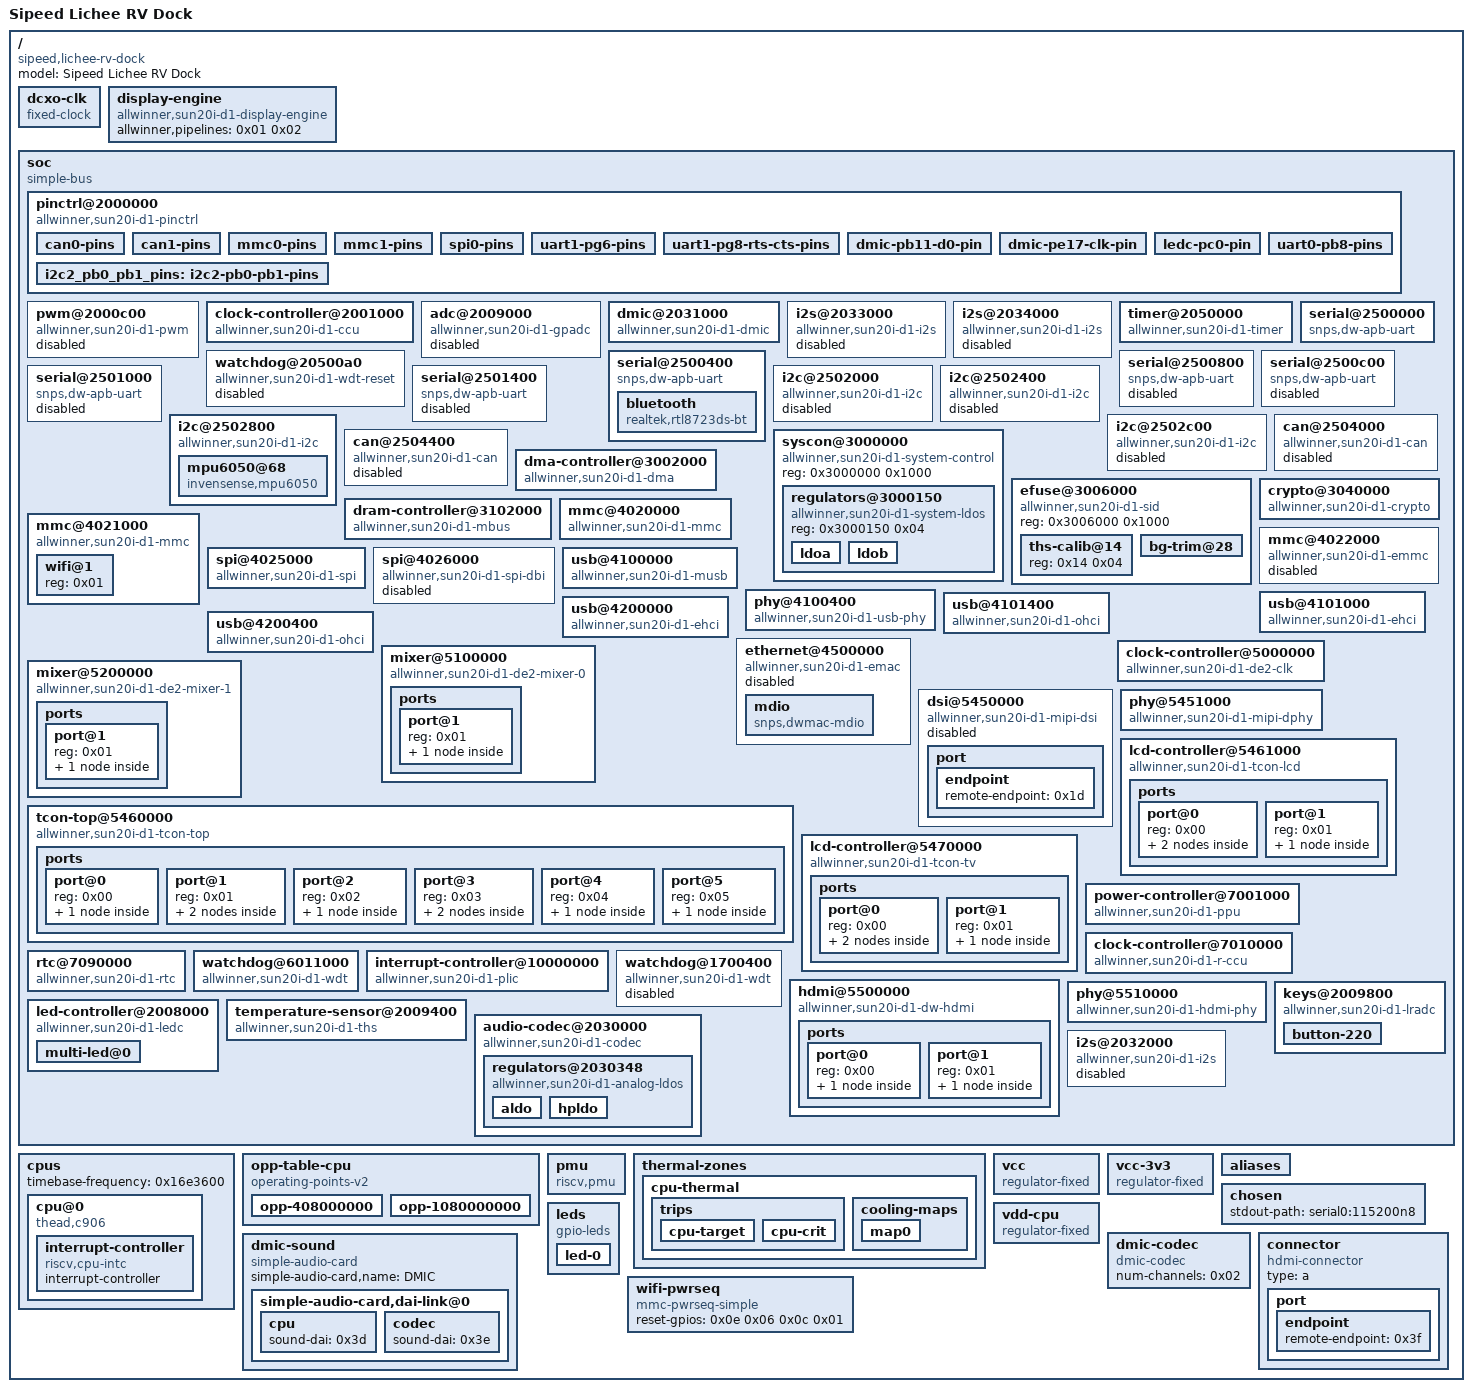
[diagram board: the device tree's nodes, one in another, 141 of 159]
/dts-v1/;

/ {
	#address-cells = <0x01>;
	#size-cells = <0x01>;
	model = "Sipeed Lichee RV Dock";
	compatible = "sipeed,lichee-rv-dock\0sipeed,lichee-rv\0allwinner,sun20i-d1";

	dcxo-clk {
		compatible = "fixed-clock";
		clock-output-names = "dcxo";
		#clock-cells = <0x00>;
		clock-frequency = <0x16e3600>;
		phandle = <0x05>;
	};

	display-engine {
		compatible = "allwinner,sun20i-d1-display-engine";
		allwinner,pipelines = <0x01 0x02>;
		status = "okay";
	};

	soc {
		compatible = "simple-bus";
		ranges;
		dma-noncoherent;
		#address-cells = <0x01>;
		#size-cells = <0x01>;
		interrupt-parent = <0x03>;

		pinctrl@2000000 {
			compatible = "allwinner,sun20i-d1-pinctrl";
			reg = <0x2000000 0x800>;
			interrupts = <0x55 0x04 0x57 0x04 0x59 0x04 0x5b 0x04 0x5d 0x04 0x5f 0x04>;
			clocks = <0x04 0x18 0x05 0x06 0x00>;
			clock-names = "apb\0hosc\0losc";
			gpio-controller;
			interrupt-controller;
			#gpio-cells = <0x03>;
			#interrupt-cells = <0x03>;
			vcc-pb-supply = <0x07>;
			vcc-pc-supply = <0x07>;
			vcc-pd-supply = <0x07>;
			vcc-pe-supply = <0x07>;
			vcc-pf-supply = <0x07>;
			vcc-pg-supply = <0x07>;
			phandle = <0x0e>;

			can0-pins {
				pins = "PB2\0PB3";
				function = "can0";
				phandle = <0x0f>;
			};

			can1-pins {
				pins = "PB4\0PB5";
				function = "can1";
				phandle = <0x10>;
			};

			mmc0-pins {
				pins = "PF0\0PF1\0PF2\0PF3\0PF4\0PF5";
				function = "mmc0";
				phandle = <0x11>;
			};

			mmc1-pins {
				pins = "PG0\0PG1\0PG2\0PG3\0PG4\0PG5";
				function = "mmc1";
				phandle = <0x13>;
			};

			spi0-pins {
				pins = "PC2\0PC3\0PC4\0PC5\0PC6\0PC7";
				function = "spi0";
				phandle = <0x14>;
			};

			uart1-pg6-pins {
				pins = "PG6\0PG7";
				function = "uart1";
				phandle = <0x0c>;
			};

			uart1-pg8-rts-cts-pins {
				pins = "PG8\0PG9";
				function = "uart1";
				phandle = <0x0d>;
			};

			dmic-pb11-d0-pin {
				pins = "PB11";
				function = "dmic";
				phandle = <0x09>;
			};

			dmic-pe17-clk-pin {
				pins = "PE17";
				function = "dmic";
				phandle = <0x0a>;
			};

			ledc-pc0-pin {
				pins = "PC0";
				function = "ledc";
				phandle = <0x32>;
			};

			uart0-pb8-pins {
				pins = "PB8\0PB9";
				function = "uart0";
				phandle = <0x0b>;
			};

			i2c2_pb0_pb1_pins: i2c2-pb0-pb1-pins {
    				pins = "PB0", "PB1";
    				function = "i2c2";
			};
		};

		pwm@2000c00 {
			compatible = "allwinner,sun20i-d1-pwm";
			reg = <0x2000c00 0x400>;
			clocks = <0x04 0x2d 0x05 0x04 0x18>;
			clock-names = "bus\0hosc\0apb0";
			resets = <0x04 0x0d>;
			status = "disabled";
			#pwm-cells = <0x03>;
		};

		clock-controller@2001000 {
			compatible = "allwinner,sun20i-d1-ccu";
			reg = <0x2001000 0x1000>;
			clocks = <0x05 0x06 0x00 0x06 0x02>;
			clock-names = "hosc\0losc\0iosc";
			#clock-cells = <0x01>;
			#reset-cells = <0x01>;
			phandle = <0x04>;
		};

		adc@2009000 {
			compatible = "allwinner,sun20i-d1-gpadc";
			reg = <0x2009000 0x400>;
			clocks = <0x04 0x50>;
			resets = <0x04 0x20>;
			interrupts = <0x49 0x04>;
			status = "disabled";
			#io-channel-cells = <0x01>;
		};

		dmic@2031000 {
			compatible = "allwinner,sun20i-d1-dmic\0allwinner,sun50i-h6-dmic";
			reg = <0x2031000 0x400>;
			interrupts = <0x28 0x04>;
			clocks = <0x04 0x5d 0x04 0x5c>;
			clock-names = "bus\0mod";
			resets = <0x04 0x26>;
			dmas = <0x08 0x08>;
			dma-names = "rx";
			status = "okay";
			#sound-dai-cells = <0x00>;
			pinctrl-0 = <0x09 0x0a>;
			pinctrl-names = "default";
			phandle = <0x3d>;
		};

		i2s@2033000 {
			compatible = "allwinner,sun20i-d1-i2s\0allwinner,sun50i-r329-i2s";
			reg = <0x2033000 0x1000>;
			interrupts = <0x2b 0x04>;
			clocks = <0x04 0x57 0x04 0x53>;
			clock-names = "apb\0mod";
			resets = <0x04 0x23>;
			dmas = <0x08 0x04 0x08 0x04>;
			dma-names = "rx\0tx";
			status = "disabled";
			#sound-dai-cells = <0x00>;
		};

		i2s@2034000 {
			compatible = "allwinner,sun20i-d1-i2s\0allwinner,sun50i-r329-i2s";
			reg = <0x2034000 0x1000>;
			interrupts = <0x2c 0x04>;
			clocks = <0x04 0x58 0x04 0x54>;
			clock-names = "apb\0mod";
			resets = <0x04 0x24>;
			dmas = <0x08 0x05 0x08 0x05>;
			dma-names = "rx\0tx";
			status = "disabled";
			#sound-dai-cells = <0x00>;
		};

		timer@2050000 {
			compatible = "allwinner,sun20i-d1-timer\0allwinner,sun8i-a23-timer";
			reg = <0x2050000 0xa0>;
			interrupts = <0x4b 0x04 0x4c 0x04>;
			clocks = <0x05>;
		};

		watchdog@20500a0 {
			compatible = "allwinner,sun20i-d1-wdt-reset\0allwinner,sun20i-d1-wdt";
			reg = <0x20500a0 0x20>;
			interrupts = <0x4f 0x04>;
			clocks = <0x05 0x06 0x00>;
			clock-names = "hosc\0losc";
			status = "reserved";
		};

		serial@2500000 {
			compatible = "snps,dw-apb-uart";
			reg = <0x2500000 0x400>;
			reg-io-width = <0x04>;
			reg-shift = <0x02>;
			interrupts = <0x12 0x04>;
			clocks = <0x04 0x3e>;
			resets = <0x04 0x12>;
			dmas = <0x08 0x0e 0x08 0x0e>;
			dma-names = "tx\0rx";
			status = "okay";
			pinctrl-0 = <0x0b>;
			pinctrl-names = "default";
		};

		serial@2500400 {
			compatible = "snps,dw-apb-uart";
			reg = <0x2500400 0x400>;
			reg-io-width = <0x04>;
			reg-shift = <0x02>;
			interrupts = <0x13 0x04>;
			clocks = <0x04 0x3f>;
			resets = <0x04 0x13>;
			dmas = <0x08 0x0f 0x08 0x0f>;
			dma-names = "tx\0rx";
			status = "okay";
			uart-has-rtscts;
			pinctrl-0 = <0x0c 0x0d>;
			pinctrl-names = "default";

			bluetooth {
				compatible = "realtek,rtl8723ds-bt";
				device-wake-gpios = <0x0e 0x06 0x0f 0x00>;
				enable-gpios = <0x0e 0x06 0x12 0x00>;
				host-wake-gpios = <0x0e 0x06 0x11 0x00>;
			};
		};

		serial@2500800 {
			compatible = "snps,dw-apb-uart";
			reg = <0x2500800 0x400>;
			reg-io-width = <0x04>;
			reg-shift = <0x02>;
			interrupts = <0x14 0x04>;
			clocks = <0x04 0x40>;
			resets = <0x04 0x14>;
			dmas = <0x08 0x10 0x08 0x10>;
			dma-names = "tx\0rx";
			status = "disabled";
		};

		serial@2500c00 {
			compatible = "snps,dw-apb-uart";
			reg = <0x2500c00 0x400>;
			reg-io-width = <0x04>;
			reg-shift = <0x02>;
			interrupts = <0x15 0x04>;
			clocks = <0x04 0x41>;
			resets = <0x04 0x15>;
			dmas = <0x08 0x11 0x08 0x11>;
			dma-names = "tx\0rx";
			status = "disabled";
		};

		serial@2501000 {
			compatible = "snps,dw-apb-uart";
			reg = <0x2501000 0x400>;
			reg-io-width = <0x04>;
			reg-shift = <0x02>;
			interrupts = <0x16 0x04>;
			clocks = <0x04 0x42>;
			resets = <0x04 0x16>;
			dmas = <0x08 0x12 0x08 0x12>;
			dma-names = "tx\0rx";
			status = "disabled";
		};

		serial@2501400 {
			compatible = "snps,dw-apb-uart";
			reg = <0x2501400 0x400>;
			reg-io-width = <0x04>;
			reg-shift = <0x02>;
			interrupts = <0x17 0x04>;
			clocks = <0x04 0x43>;
			resets = <0x04 0x17>;
			dmas = <0x08 0x13 0x08 0x13>;
			dma-names = "tx\0rx";
			status = "disabled";
		};

		i2c@2502000 {
			compatible = "allwinner,sun20i-d1-i2c\0allwinner,sun8i-v536-i2c\0allwinner,sun6i-a31-i2c";
			reg = <0x2502000 0x400>;
			interrupts = <0x19 0x04>;
			clocks = <0x04 0x44>;
			resets = <0x04 0x18>;
			dmas = <0x08 0x2b 0x08 0x2b>;
			dma-names = "rx\0tx";
			status = "disabled";
			#address-cells = <0x01>;
			#size-cells = <0x00>;
		};

		i2c@2502400 {
			compatible = "allwinner,sun20i-d1-i2c\0allwinner,sun8i-v536-i2c\0allwinner,sun6i-a31-i2c";
			reg = <0x2502400 0x400>;
			interrupts = <0x1a 0x04>;
			clocks = <0x04 0x45>;
			resets = <0x04 0x19>;
			dmas = <0x08 0x2c 0x08 0x2c>;
			dma-names = "rx\0tx";
			status = "disabled";
			#address-cells = <0x01>;
			#size-cells = <0x00>;
		};

		i2c@2502800 {
			compatible = "allwinner,sun20i-d1-i2c\0allwinner,sun8i-v536-i2c\0allwinner,sun6i-a31-i2c";
			reg = <0x2502800 0x400>;
			interrupts = <0x1b 0x04>;
			clocks = <0x04 0x46>;
			resets = <0x04 0x1a>;
			dmas = <0x08 0x2d 0x08 0x2d>;
			dma-names = "rx\0tx";
			pinctrl-names = "default";
    			pinctrl-0 = <&i2c2_pb0_pb1_pins>;
			status = "okay";
			#address-cells = <0x01>;
			#size-cells = <0x00>;
			
			mpu6050@68 {
        			compatible = "invensense,mpu6050";
        			reg = <0x68>;
        			mount-matrix = "1", "0", "0", "0", "1", "0", "0", "0", "1";
    			};	
		};

		i2c@2502c00 {
			compatible = "allwinner,sun20i-d1-i2c\0allwinner,sun8i-v536-i2c\0allwinner,sun6i-a31-i2c";
			reg = <0x2502c00 0x400>;
			interrupts = <0x1c 0x04>;
			clocks = <0x04 0x47>;
			resets = <0x04 0x1b>;
			dmas = <0x08 0x2e 0x08 0x2e>;
			dma-names = "rx\0tx";
			status = "disabled";
			#address-cells = <0x01>;
			#size-cells = <0x00>;
		};

		can@2504000 {
			compatible = "allwinner,sun20i-d1-can";
			reg = <0x2504000 0x400>;
			interrupts = <0x25 0x04>;
			clocks = <0x04 0x91>;
			resets = <0x04 0x42>;
			pinctrl-names = "default";
			pinctrl-0 = <0x0f>;
			status = "disabled";
		};

		can@2504400 {
			compatible = "allwinner,sun20i-d1-can";
			reg = <0x2504400 0x400>;
			interrupts = <0x26 0x04>;
			clocks = <0x04 0x92>;
			resets = <0x04 0x43>;
			pinctrl-names = "default";
			pinctrl-0 = <0x10>;
			status = "disabled";
		};

		syscon@3000000 {
			compatible = "allwinner,sun20i-d1-system-control";
			reg = <0x3000000 0x1000>;
			ranges;
			#address-cells = <0x01>;
			#size-cells = <0x01>;
			phandle = <0x17>;

			regulators@3000150 {
				compatible = "allwinner,sun20i-d1-system-ldos";
				reg = <0x3000150 0x04>;

				ldoa {
					regulator-always-on;
					regulator-min-microvolt = <0x1b7740>;
					regulator-max-microvolt = <0x1b7740>;
					ldo-in-supply = <0x07>;
					phandle = <0x2f>;
				};

				ldob {
				};
			};
		};

		dma-controller@3002000 {
			compatible = "allwinner,sun20i-d1-dma";
			reg = <0x3002000 0x1000>;
			interrupts = <0x42 0x04>;
			clocks = <0x04 0x25 0x04 0x30>;
			clock-names = "bus\0mbus";
			resets = <0x04 0x06>;
			dma-channels = <0x10>;
			dma-requests = <0x30>;
			#dma-cells = <0x01>;
			phandle = <0x08>;
		};

		efuse@3006000 {
			compatible = "allwinner,sun20i-d1-sid";
			reg = <0x3006000 0x1000>;
			#address-cells = <0x01>;
			#size-cells = <0x01>;

			ths-calib@14 {
				reg = <0x14 0x04>;
				phandle = <0x33>;
			};

			bg-trim@28 {
				reg = <0x28 0x04>;
				bits = <0x10 0x08>;
				phandle = <0x36>;
			};
		};

		crypto@3040000 {
			compatible = "allwinner,sun20i-d1-crypto";
			reg = <0x3040000 0x800>;
			interrupts = <0x44 0x04>;
			clocks = <0x04 0x22 0x04 0x21 0x04 0x32 0x06 0x02>;
			clock-names = "bus\0mod\0ram\0trng";
			resets = <0x04 0x04>;
		};

		dram-controller@3102000 {
			compatible = "allwinner,sun20i-d1-mbus";
			reg = <0x3102000 0x1000 0x3103000 0x1000>;
			reg-names = "mbus\0dram";
			interrupts = <0x3b 0x04>;
			clocks = <0x04 0x1a 0x04 0x2f 0x04 0x37>;
			clock-names = "mbus\0dram\0bus";
			dma-ranges = <0x00 0x40000000 0x80000000>;
			#address-cells = <0x01>;
			#size-cells = <0x01>;
			#interconnect-cells = <0x01>;
		};

		mmc@4020000 {
			compatible = "allwinner,sun20i-d1-mmc";
			reg = <0x4020000 0x1000>;
			interrupts = <0x38 0x04>;
			clocks = <0x04 0x3b 0x04 0x38>;
			clock-names = "ahb\0mmc";
			resets = <0x04 0x0f>;
			reset-names = "ahb";
			cap-sd-highspeed;
			max-frequency = <0x8f0d180>;
			no-mmc;
			status = "okay";
			#address-cells = <0x01>;
			#size-cells = <0x00>;
			broken-cd;
			bus-width = <0x04>;
			disable-wp;
			vmmc-supply = <0x07>;
			vqmmc-supply = <0x07>;
			pinctrl-0 = <0x11>;
			pinctrl-names = "default";
		};

		mmc@4021000 {
			compatible = "allwinner,sun20i-d1-mmc";
			reg = <0x4021000 0x1000>;
			interrupts = <0x39 0x04>;
			clocks = <0x04 0x3c 0x04 0x39>;
			clock-names = "ahb\0mmc";
			resets = <0x04 0x10>;
			reset-names = "ahb";
			cap-sd-highspeed;
			max-frequency = <0x8f0d180>;
			no-mmc;
			status = "okay";
			#address-cells = <0x01>;
			#size-cells = <0x00>;
			bus-width = <0x04>;
			mmc-pwrseq = <0x12>;
			non-removable;
			vmmc-supply = <0x07>;
			vqmmc-supply = <0x07>;
			pinctrl-0 = <0x13>;
			pinctrl-names = "default";

			wifi@1 {
				reg = <0x01>;
			};
		};

		mmc@4022000 {
			compatible = "allwinner,sun20i-d1-emmc\0allwinner,sun50i-a100-emmc";
			reg = <0x4022000 0x1000>;
			interrupts = <0x3a 0x04>;
			clocks = <0x04 0x3d 0x04 0x3a>;
			clock-names = "ahb\0mmc";
			resets = <0x04 0x11>;
			reset-names = "ahb";
			cap-mmc-highspeed;
			max-frequency = <0x8f0d180>;
			mmc-ddr-1_8v;
			mmc-ddr-3_3v;
			no-sd;
			no-sdio;
			status = "disabled";
			#address-cells = <0x01>;
			#size-cells = <0x00>;
		};

		spi@4025000 {
			compatible = "allwinner,sun20i-d1-spi\0allwinner,sun50i-r329-spi";
			reg = <0x4025000 0x1000>;
			interrupts = <0x1f 0x04>;
			clocks = <0x04 0x4a 0x04 0x48>;
			clock-names = "ahb\0mod";
			dmas = <0x08 0x16 0x08 0x16>;
			dma-names = "rx\0tx";
			resets = <0x04 0x1c>;
			status = "okay";
			#address-cells = <0x01>;
			#size-cells = <0x00>;
			pinctrl-0 = <0x14>;
			pinctrl-names = "default";
		};

		spi@4026000 {
			compatible = "allwinner,sun20i-d1-spi-dbi\0allwinner,sun50i-r329-spi-dbi\0allwinner,sun50i-r329-spi";
			reg = <0x4026000 0x1000>;
			interrupts = <0x20 0x04>;
			clocks = <0x04 0x4b 0x04 0x49>;
			clock-names = "ahb\0mod";
			dmas = <0x08 0x17 0x08 0x17>;
			dma-names = "rx\0tx";
			resets = <0x04 0x1d>;
			status = "disabled";
			#address-cells = <0x01>;
			#size-cells = <0x00>;
		};

		usb@4100000 {
			compatible = "allwinner,sun20i-d1-musb\0allwinner,sun8i-a33-musb";
			reg = <0x4100000 0x400>;
			interrupts = <0x2d 0x04>;
			interrupt-names = "mc";
			clocks = <0x04 0x67>;
			resets = <0x04 0x2e>;
			extcon = <0x15 0x00>;
			phys = <0x15 0x00>;
			phy-names = "usb";
			status = "okay";
			dr_mode = "otg";
		};

		phy@4100400 {
			compatible = "allwinner,sun20i-d1-usb-phy";
			reg = <0x4100400 0x100 0x4101800 0x100 0x4200800 0x100>;
			reg-names = "phy_ctrl\0pmu0\0pmu1";
			clocks = <0x05 0x05>;
			clock-names = "usb0_phy\0usb1_phy";
			resets = <0x04 0x28 0x04 0x29>;
			reset-names = "usb0_reset\0usb1_reset";
			status = "okay";
			#phy-cells = <0x01>;
			usb0_id_det-gpios = <0x0e 0x03 0x15 0x00>;
			usb0_vbus_det-gpios = <0x0e 0x03 0x14 0x00>;
			usb0_vbus-supply = <0x16>;
			usb1_vbus-supply = <0x16>;
			phandle = <0x15>;
		};

		usb@4101000 {
			compatible = "allwinner,sun20i-d1-ehci\0generic-ehci";
			reg = <0x4101000 0x100>;
			interrupts = <0x2e 0x04>;
			clocks = <0x04 0x63 0x04 0x65 0x04 0x61>;
			resets = <0x04 0x2a 0x04 0x2c>;
			phys = <0x15 0x00>;
			phy-names = "usb";
			status = "okay";
		};

		usb@4101400 {
			compatible = "allwinner,sun20i-d1-ohci\0generic-ohci";
			reg = <0x4101400 0x100>;
			interrupts = <0x2f 0x04>;
			clocks = <0x04 0x63 0x04 0x61>;
			resets = <0x04 0x2a>;
			phys = <0x15 0x00>;
			phy-names = "usb";
			status = "okay";
		};

		usb@4200000 {
			compatible = "allwinner,sun20i-d1-ehci\0generic-ehci";
			reg = <0x4200000 0x100>;
			interrupts = <0x31 0x04>;
			clocks = <0x04 0x64 0x04 0x66 0x04 0x62>;
			resets = <0x04 0x2b 0x04 0x2d>;
			phys = <0x15 0x01>;
			phy-names = "usb";
			status = "okay";
		};

		usb@4200400 {
			compatible = "allwinner,sun20i-d1-ohci\0generic-ohci";
			reg = <0x4200400 0x100>;
			interrupts = <0x32 0x04>;
			clocks = <0x04 0x64 0x04 0x62>;
			resets = <0x04 0x2b>;
			phys = <0x15 0x01>;
			phy-names = "usb";
			status = "okay";
		};

		ethernet@4500000 {
			compatible = "allwinner,sun20i-d1-emac\0allwinner,sun50i-a64-emac";
			reg = <0x4500000 0x10000>;
			interrupts = <0x3e 0x04>;
			interrupt-names = "macirq";
			clocks = <0x04 0x4d>;
			clock-names = "stmmaceth";
			resets = <0x04 0x1e>;
			reset-names = "stmmaceth";
			syscon = <0x17>;
			status = "disabled";

			mdio {
				compatible = "snps,dwmac-mdio";
				#address-cells = <0x01>;
				#size-cells = <0x00>;
			};
		};

		clock-controller@5000000 {
			compatible = "allwinner,sun20i-d1-de2-clk\0allwinner,sun50i-h5-de2-clk";
			reg = <0x5000000 0x10000>;
			clocks = <0x04 0x1c 0x04 0x1b>;
			clock-names = "bus\0mod";
			resets = <0x04 0x01>;
			#clock-cells = <0x01>;
			#reset-cells = <0x01>;
			phandle = <0x18>;
		};

		mixer@5100000 {
			compatible = "allwinner,sun20i-d1-de2-mixer-0";
			reg = <0x5100000 0x100000>;
			clocks = <0x18 0x00 0x18 0x06>;
			clock-names = "bus\0mod";
			resets = <0x18 0x00>;
			phandle = <0x01>;

			ports {
				#address-cells = <0x01>;
				#size-cells = <0x00>;

				port@1 {
					reg = <0x01>;

					endpoint {
						remote-endpoint = <0x19>;
						phandle = <0x1e>;
					};
				};
			};
		};

		mixer@5200000 {
			compatible = "allwinner,sun20i-d1-de2-mixer-1";
			reg = <0x5200000 0x100000>;
			clocks = <0x18 0x01 0x18 0x07>;
			clock-names = "bus\0mod";
			resets = <0x18 0x01>;
			phandle = <0x02>;

			ports {
				#address-cells = <0x01>;
				#size-cells = <0x00>;

				port@1 {
					reg = <0x01>;

					endpoint {
						remote-endpoint = <0x1a>;
						phandle = <0x21>;
					};
				};
			};
		};

		dsi@5450000 {
			compatible = "allwinner,sun20i-d1-mipi-dsi\0allwinner,sun50i-a100-mipi-dsi";
			reg = <0x5450000 0x1000>;
			interrupts = <0x6c 0x04>;
			clocks = <0x04 0x6f 0x1b 0x02>;
			clock-names = "bus\0mod";
			resets = <0x04 0x33>;
			phys = <0x1c>;
			phy-names = "dphy";
			status = "disabled";

			port {

				endpoint {
					remote-endpoint = <0x1d>;
					phandle = <0x28>;
				};
			};
		};

		phy@5451000 {
			compatible = "allwinner,sun20i-d1-mipi-dphy\0allwinner,sun50i-a100-mipi-dphy";
			reg = <0x5451000 0x1000>;
			interrupts = <0x6c 0x04>;
			clocks = <0x04 0x6f 0x04 0x6e>;
			clock-names = "bus\0mod";
			resets = <0x04 0x33>;
			#phy-cells = <0x00>;
			phandle = <0x1c>;
		};

		tcon-top@5460000 {
			compatible = "allwinner,sun20i-d1-tcon-top";
			reg = <0x5460000 0x1000>;
			clocks = <0x04 0x69 0x04 0x72 0x04 0x74 0x04 0x70>;
			clock-names = "bus\0tcon-tv0\0tve0\0dsi";
			clock-output-names = "tcon-top-tv0\0tcon-top-dsi";
			resets = <0x04 0x30>;
			#clock-cells = <0x01>;
			phandle = <0x1b>;

			ports {
				#address-cells = <0x01>;
				#size-cells = <0x00>;

				port@0 {
					reg = <0x00>;

					endpoint {
						remote-endpoint = <0x1e>;
						phandle = <0x19>;
					};
				};

				port@1 {
					reg = <0x01>;
					#address-cells = <0x01>;
					#size-cells = <0x00>;

					endpoint@0 {
						reg = <0x00>;
						remote-endpoint = <0x1f>;
						phandle = <0x26>;
					};

					endpoint@2 {
						reg = <0x02>;
						remote-endpoint = <0x20>;
						phandle = <0x29>;
					};
				};

				port@2 {
					reg = <0x02>;
					#address-cells = <0x01>;
					#size-cells = <0x00>;

					endpoint@1 {
						reg = <0x01>;
						remote-endpoint = <0x21>;
						phandle = <0x1a>;
					};
				};

				port@3 {
					reg = <0x03>;
					#address-cells = <0x01>;
					#size-cells = <0x00>;

					endpoint@0 {
						reg = <0x00>;
						remote-endpoint = <0x22>;
						phandle = <0x27>;
					};

					endpoint@2 {
						reg = <0x02>;
						remote-endpoint = <0x23>;
						phandle = <0x2a>;
					};
				};

				port@4 {
					reg = <0x04>;

					endpoint {
						remote-endpoint = <0x24>;
						phandle = <0x2b>;
					};
				};

				port@5 {
					reg = <0x05>;

					endpoint {
						remote-endpoint = <0x25>;
						phandle = <0x30>;
					};
				};
			};
		};

		lcd-controller@5461000 {
			compatible = "allwinner,sun20i-d1-tcon-lcd";
			reg = <0x5461000 0x1000>;
			interrupts = <0x6a 0x04>;
			clocks = <0x04 0x71 0x04 0x70>;
			clock-names = "ahb\0tcon-ch0";
			clock-output-names = "tcon-pixel-clock";
			resets = <0x04 0x34 0x04 0x36>;
			reset-names = "lcd\0lvds";
			phys = <0x1c>;
			phy-names = "lvds0";
			#clock-cells = <0x00>;

			ports {
				#address-cells = <0x01>;
				#size-cells = <0x00>;

				port@0 {
					reg = <0x00>;
					#address-cells = <0x01>;
					#size-cells = <0x00>;

					endpoint@0 {
						reg = <0x00>;
						remote-endpoint = <0x26>;
						phandle = <0x1f>;
					};

					endpoint@1 {
						reg = <0x01>;
						remote-endpoint = <0x27>;
						phandle = <0x22>;
					};
				};

				port@1 {
					reg = <0x01>;
					#address-cells = <0x01>;
					#size-cells = <0x00>;

					endpoint@1 {
						reg = <0x01>;
						remote-endpoint = <0x28>;
						phandle = <0x1d>;
					};
				};
			};
		};

		lcd-controller@5470000 {
			compatible = "allwinner,sun20i-d1-tcon-tv";
			reg = <0x5470000 0x1000>;
			interrupts = <0x6b 0x04>;
			clocks = <0x04 0x73 0x1b 0x00>;
			clock-names = "ahb\0tcon-ch1";
			resets = <0x04 0x35>;
			reset-names = "lcd";

			ports {
				#address-cells = <0x01>;
				#size-cells = <0x00>;

				port@0 {
					reg = <0x00>;
					#address-cells = <0x01>;
					#size-cells = <0x00>;

					endpoint@0 {
						reg = <0x00>;
						remote-endpoint = <0x29>;
						phandle = <0x20>;
					};

					endpoint@1 {
						reg = <0x01>;
						remote-endpoint = <0x2a>;
						phandle = <0x23>;
					};
				};

				port@1 {
					reg = <0x01>;

					endpoint {
						remote-endpoint = <0x2b>;
						phandle = <0x24>;
					};
				};
			};
		};

		power-controller@7001000 {
			compatible = "allwinner,sun20i-d1-ppu";
			reg = <0x7001000 0x1000>;
			clocks = <0x2c 0x04>;
			resets = <0x2c 0x02>;
			#power-domain-cells = <0x01>;
		};

		clock-controller@7010000 {
			compatible = "allwinner,sun20i-d1-r-ccu";
			reg = <0x7010000 0x400>;
			clocks = <0x05 0x06 0x00 0x06 0x02 0x04 0x06>;
			clock-names = "hosc\0losc\0iosc\0pll-periph";
			#clock-cells = <0x01>;
			#reset-cells = <0x01>;
			phandle = <0x2c>;
		};

		rtc@7090000 {
			compatible = "allwinner,sun20i-d1-rtc\0allwinner,sun50i-r329-rtc";
			reg = <0x7090000 0x400>;
			interrupts = <0xa0 0x04>;
			clocks = <0x2c 0x07 0x05 0x2c 0x00>;
			clock-names = "bus\0hosc\0ahb";
			#clock-cells = <0x01>;
			phandle = <0x06>;
		};

		watchdog@6011000 {
			compatible = "allwinner,sun20i-d1-wdt";
			reg = <0x6011000 0x20>;
			interrupts = <0x93 0x04>;
			clocks = <0x05 0x06 0x00>;
			clock-names = "hosc\0losc";
		};

		interrupt-controller@10000000 {
			compatible = "allwinner,sun20i-d1-plic\0thead,c900-plic";
			reg = <0x10000000 0x4000000>;
			interrupts-extended = <0x2d 0x0b 0x2d 0x09>;
			interrupt-controller;
			riscv,ndev = <0xaf>;
			#address-cells = <0x00>;
			#interrupt-cells = <0x02>;
			phandle = <0x03>;
		};

		watchdog@1700400 {
			compatible = "allwinner,sun20i-d1-wdt";
			reg = <0x1700400 0x20>;
			interrupts = <0x8a 0x04>;
			clocks = <0x05 0x06 0x00>;
			clock-names = "hosc\0losc";
			status = "reserved";
		};

		hdmi@5500000 {
			compatible = "allwinner,sun20i-d1-dw-hdmi";
			reg = <0x5500000 0x10000>;
			reg-io-width = <0x01>;
			interrupts = <0x6d 0x04>;
			clocks = <0x04 0x6d 0x04 0x6a 0x04 0x6c>;
			clock-names = "iahb\0isfr\0cec";
			resets = <0x04 0x31>;
			reset-names = "ctrl";
			phys = <0x2e>;
			phy-names = "phy";
			status = "okay";
			hvcc-supply = <0x2f>;

			ports {
				#address-cells = <0x01>;
				#size-cells = <0x00>;

				port@0 {
					reg = <0x00>;

					endpoint {
						remote-endpoint = <0x30>;
						phandle = <0x25>;
					};
				};

				port@1 {
					reg = <0x01>;

					endpoint {
						remote-endpoint = <0x31>;
						phandle = <0x3f>;
					};
				};
			};
		};

		phy@5510000 {
			compatible = "allwinner,sun20i-d1-hdmi-phy";
			reg = <0x5510000 0x10000>;
			clocks = <0x04 0x6d 0x04 0x6a>;
			clock-names = "bus\0mod";
			resets = <0x04 0x32>;
			reset-names = "phy";
			status = "okay";
			#phy-cells = <0x00>;
			phandle = <0x2e>;
		};

		led-controller@2008000 {
			compatible = "allwinner,sun20i-d1-ledc\0allwinner,sun50i-a100-ledc";
			reg = <0x2008000 0x400>;
			interrupts = <0x24 0x04>;
			clocks = <0x04 0x7b 0x04 0x7a>;
			clock-names = "bus\0mod";
			resets = <0x04 0x3b>;
			dmas = <0x08 0x2a>;
			dma-names = "tx";
			status = "okay";
			#address-cells = <0x01>;
			#size-cells = <0x00>;
			pinctrl-0 = <0x32>;
			pinctrl-names = "default";

			multi-led@0 {
				reg = <0x00>;
				color = <0x09>;
				function = "status";
			};
		};

		temperature-sensor@2009400 {
			compatible = "allwinner,sun20i-d1-ths";
			reg = <0x2009400 0x400>;
			interrupts = <0x4a 0x04>;
			clocks = <0x04 0x51 0x05>;
			clock-names = "bus\0mod";
			resets = <0x04 0x21>;
			nvmem-cells = <0x33>;
			nvmem-cell-names = "calibration";
			#thermal-sensor-cells = <0x00>;
			vref-supply = <0x34>;
			phandle = <0x39>;
		};

		keys@2009800 {
			compatible = "allwinner,sun20i-d1-lradc\0allwinner,sun50i-r329-lradc";
			reg = <0x2009800 0x400>;
			interrupts = <0x4d 0x04>;
			clocks = <0x04 0x68>;
			resets = <0x04 0x2f>;
			vref-supply = <0x34>;
			status = "okay";

			button-220 {
				label = "OK";
				linux,code = <0x160>;
				channel = <0x00>;
				voltage = <0x35b60>;
			};
		};

		audio-codec@2030000 {
			compatible = "allwinner,sun20i-d1-codec\0simple-mfd\0syscon";
			reg = <0x2030000 0x1000>;
			interrupts = <0x29 0x04>;
			clocks = <0x04 0x60 0x04 0x5f 0x04 0x5e 0x05 0x06 0x00>;
			clock-names = "bus\0adc\0dac\0hosc\0losc";
			resets = <0x04 0x27>;
			dmas = <0x08 0x07 0x08 0x07>;
			dma-names = "rx\0tx";
			avcc-supply = <0x34>;
			hpvcc-supply = <0x35>;
			#address-cells = <0x01>;
			#size-cells = <0x01>;
			#sound-dai-cells = <0x00>;
			routing = "Internal Speaker\0HPOUTL\0Internal Speaker\0HPOUTR\0LINEINL\0HPOUTL\0LINEINR\0HPOUTR\0MICIN3\0Internal Microphone\0Internal Microphone\0HBIAS";
			widgets = "Microphone\0Internal Microphone\0Speaker\0Internal Speaker";
			status = "okay";

			regulators@2030348 {
				compatible = "allwinner,sun20i-d1-analog-ldos";
				reg = <0x2030348 0x04>;
				nvmem-cells = <0x36>;
				nvmem-cell-names = "bg_trim";

				aldo {
					regulator-min-microvolt = <0x1b7740>;
					regulator-max-microvolt = <0x1b7740>;
					regulator-always-on;
					vdd33-supply = <0x07>;
					phandle = <0x34>;
				};

				hpldo {
					regulator-min-microvolt = <0x1b7740>;
					regulator-max-microvolt = <0x1b7740>;
					hpldoin-supply = <0x07>;
					phandle = <0x35>;
				};
			};
		};

		i2s@2032000 {
			compatible = "allwinner,sun20i-d1-i2s\0allwinner,sun50i-r329-i2s";
			reg = <0x2032000 0x1000>;
			interrupts = <0x2a 0x04>;
			clocks = <0x04 0x56 0x04 0x52>;
			clock-names = "apb\0mod";
			resets = <0x04 0x22>;
			dmas = <0x08 0x03 0x08 0x03>;
			dma-names = "rx\0tx";
			status = "disabled";
			#sound-dai-cells = <0x00>;
		};
	};

	cpus {
		timebase-frequency = <0x16e3600>;
		#address-cells = <0x01>;
		#size-cells = <0x00>;

		cpu@0 {
			compatible = "thead,c906\0riscv";
			device_type = "cpu";
			reg = <0x00>;
			clocks = <0x04 0x84>;
			d-cache-block-size = <0x40>;
			d-cache-sets = <0x100>;
			d-cache-size = <0x8000>;
			i-cache-block-size = <0x40>;
			i-cache-sets = <0x80>;
			i-cache-size = <0x8000>;
			mmu-type = "riscv,sv39";
			operating-points-v2 = <0x37>;
			riscv,isa = "rv64imafdc";
			riscv,isa-base = "rv64i";
			riscv,isa-extensions = "i\0m\0a\0f\0d\0c\0zicntr\0zicsr\0zifencei\0zihpm";
			#cooling-cells = <0x02>;
			cpu-supply = <0x38>;
			phandle = <0x3b>;

			interrupt-controller {
				compatible = "riscv,cpu-intc";
				interrupt-controller;
				#interrupt-cells = <0x01>;
				phandle = <0x2d>;
			};
		};
	};

	opp-table-cpu {
		compatible = "operating-points-v2";
		phandle = <0x37>;

		opp-408000000 {
			opp-hz = <0x00 0x18519600>;
			opp-microvolt = <0xdbba0 0xdbba0 0x10c8e0>;
		};

		opp-1080000000 {
			opp-hz = <0x00 0x3c14dc00>;
			opp-microvolt = <0xdbba0 0xdbba0 0x10c8e0>;
		};
	};

	pmu {
		compatible = "riscv,pmu";
		riscv,event-to-mhpmcounters = <0x03 0x03 0x08 0x04 0x04 0x10 0x05 0x05 0x200 0x06 0x06 0x100 0x10000 0x10000 0x4000 0x10001 0x10001 0x8000 0x10002 0x10002 0x10000 0x10003 0x10003 0x20000 0x10019 0x10019 0x40 0x10021 0x10021 0x20>;
		riscv,event-to-mhpmevent = <0x03 0x00 0x01 0x04 0x00 0x02 0x05 0x00 0x07 0x06 0x00 0x06 0x10000 0x00 0x0c 0x10001 0x00 0x0d 0x10002 0x00 0x0e 0x10003 0x00 0x0f 0x10019 0x00 0x04 0x10021 0x00 0x03>;
		riscv,raw-event-to-mhpmcounters = <0x00 0x01 0xffffffff 0xffffffff 0x08 0x00 0x02 0xffffffff 0xffffffff 0x10 0x00 0x03 0xffffffff 0xffffffff 0x20 0x00 0x04 0xffffffff 0xffffffff 0x40 0x00 0x05 0xffffffff 0xffffffff 0x80 0x00 0x06 0xffffffff 0xffffffff 0x100 0x00 0x07 0xffffffff 0xffffffff 0x200 0x00 0x0b 0xffffffff 0xffffffff 0x2000 0x00 0x0c 0xffffffff 0xffffffff 0x4000 0x00 0x0d 0xffffffff 0xffffffff 0x8000 0x00 0x0e 0xffffffff 0xffffffff 0x10000 0x00 0x0f 0xffffffff 0xffffffff 0x20000>;
	};

	thermal-zones {

		cpu-thermal {
			polling-delay = <0x00>;
			polling-delay-passive = <0x00>;
			thermal-sensors = <0x39>;

			trips {

				cpu-target {
					hysteresis = <0xbb8>;
					temperature = <0x14c08>;
					type = "passive";
					phandle = <0x3a>;
				};

				cpu-crit {
					hysteresis = <0x00>;
					temperature = <0x1adb0>;
					type = "critical";
				};
			};

			cooling-maps {

				map0 {
					trip = <0x3a>;
					cooling-device = <0x3b 0xffffffff 0xffffffff>;
				};
			};
		};
	};

	vcc {
		compatible = "regulator-fixed";
		regulator-name = "vcc";
		regulator-min-microvolt = <0x4c4b40>;
		regulator-max-microvolt = <0x4c4b40>;
		phandle = <0x16>;
	};

	vcc-3v3 {
		compatible = "regulator-fixed";
		regulator-name = "vcc-3v3";
		regulator-min-microvolt = <0x325aa0>;
		regulator-max-microvolt = <0x325aa0>;
		vin-supply = <0x16>;
		phandle = <0x07>;
	};

	aliases {
		serial0 = "/soc/serial@2500000";
		ethernet1 = "/soc/mmc@4021000/wifi@1";
	};

	chosen {
		stdout-path = "serial0:115200n8";
	};

	leds {
		compatible = "gpio-leds";

		led-0 {
			color = <0x02>;
			function = "status";
			gpios = <0x0e 0x02 0x01 0x00>;
		};
	};

	vdd-cpu {
		compatible = "regulator-fixed";
		regulator-name = "vdd-cpu";
		regulator-min-microvolt = <0xdbba0>;
		regulator-max-microvolt = <0xdbba0>;
		vin-supply = <0x16>;
		phandle = <0x38>;
	};

	dmic-codec {
		compatible = "dmic-codec";
		num-channels = <0x02>;
		#sound-dai-cells = <0x00>;
		phandle = <0x3e>;
	};

	dmic-sound {
		compatible = "simple-audio-card";
		simple-audio-card,name = "DMIC";
		#address-cells = <0x01>;
		#size-cells = <0x00>;

		simple-audio-card,dai-link@0 {
			reg = <0x00>;
			format = "pdm";
			frame-master = <0x3c>;
			bitclock-master = <0x3c>;

			cpu {
				sound-dai = <0x3d>;
				phandle = <0x3c>;
			};

			codec {
				sound-dai = <0x3e>;
			};
		};
	};

	connector {
		compatible = "hdmi-connector";
		type = "a";

		port {

			endpoint {
				remote-endpoint = <0x3f>;
				phandle = <0x31>;
			};
		};
	};

	wifi-pwrseq {
		compatible = "mmc-pwrseq-simple";
		reset-gpios = <0x0e 0x06 0x0c 0x01>;
		phandle = <0x12>;
	};
};
